# STM32H7RSxx register map
File version: 0.2
CPU: CM7 r0p1, little endian, MPU, FPU, 4 interrupt priority bits
Registers are 32-bit, read-write, reset 0x0 unless marked. A register's access mark holds for its fields unless they carry their own. Offsets are from the block's base; [hi:lo] are bit positions; <NAME> marks a mode.

## ADF — Audio digital filter
Base 0x4002F000
0x00 ADF_GCR — ADF global control register
  [0] TRGO — Trigger output control This bit is set by software and reset by hardware. It is used to start the acquisition of several filters synchronously. It is also used to synchronize several ADF together by controlling the adf_trgo signal.
    0=Write 0 has no effect. Read 0 means that the trigger can be set again to 1.; 1=Write 1 generates a positive pulse on the adf_trgo signal and triggers the acquisition on enabled filter having their ACQMOD[2:0] = 01x and selecting TRGO as trigger. Read 1 means that the trigger pulse is still active.
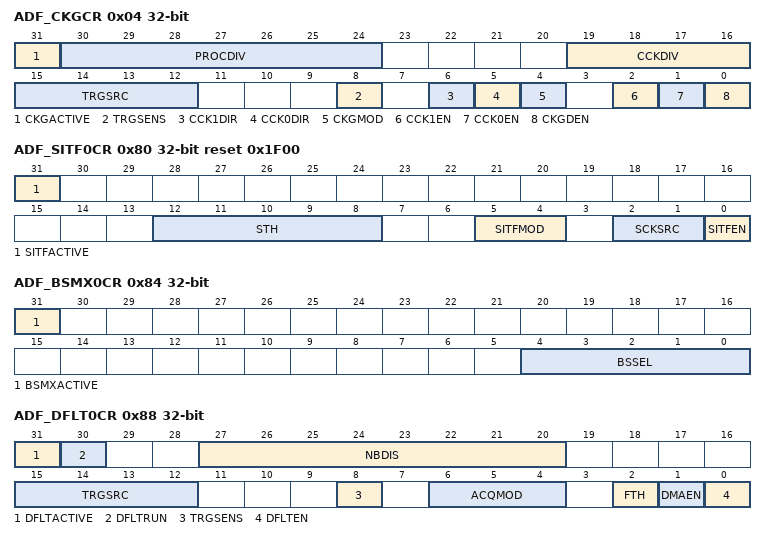
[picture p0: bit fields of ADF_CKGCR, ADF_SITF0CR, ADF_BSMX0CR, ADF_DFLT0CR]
0x04 ADF_CKGCR access per field — ADF clock generator control register
  [31] CKGACTIVE ro — Clock generator active flag This bit is set and cleared by hardware. Ii is used by the application to check if the clock generator is effectively enabled (active) or not. The protected fields of this function can only be updated when CKGACTIVE = 0 (see Section 46.4.13: Register protection for details). The delay between a transition on CKGDEN and a transition on CKGACTIVE is two periods of AHB clock and two 2 periods of adf_proc_ck.
    0=The clock generator is not active and can be configured if needed; 1=The clock generator is active and protected fields cannot be configured
  [30:24] PROCDIV rw — Divider to control the serial interface clock this field is set and reset by software. It is used to adjust the frequency of the clock provided to the SITF. This field must not be changed if the filter is enabled (DFTEN = 1). ... Note: This field can be write-protected (see Section 46.4.13: Register protection for details).
    0=adf_ker_ck provided to the SITF; 1=adf_ker_ck / 2 provided to the SITF
  [19:16] CCKDIV rw — Divider to control the ADF_CCK clock This field is set and reset by software. It is used to adjust the frequency of the ADF_CCK clock. The input clock of this divider is the clock provided to the SITF. More globally, the frequency of the ADF_CCK is given by the following formula: This field must not be changed if the filter is enabled (DFTEN = 1). ... Note: This field can be write-protected (see Section 46.4.13: Register protection for details).
    0=The ADF_CCK clock is adf_proc_ck; 1=The ADF_CCK clock is adf_proc_ck / 2; 2=The ADF_CCK clock is adf_proc_ck / 3; 15=The ADF_CCK clock is adf_proc_ck / 16
  [15:12] TRGSRC rw — Digital filter trigger signal selection This field is set and cleared by software. It is used to select which external signals trigger the corresponding filter. This field is not significant if the CKGMOD = 0. 000x: TRGO selected others: reserved Note: This field can be write-protected (see Section 46.4.13: Register protection for details).
    2=adf_trg1 selected
  [8] TRGSENS rw — CKGEN trigger sensitivity selection This bit is set and cleared by software. It is used to select the trigger sensitivity of the trigger signals. This bit is not significant if the CKGMOD = 0. Note: When the trigger source is TRGO, the sensitivity is forced to falling edge, thus TRGSENS value is not taken into account. This bit can be write-protected (see Section 46.4.13: Register protection for details).
    0=A rising edge event triggers the activation of CKGEN dividers; 1=A falling edge even triggers the activation of CKGEN dividers
  [6] CCK1DIR rw — ADF_CCK1 direction This bit is set and reset by software. It is used to control the direction of the ADF_CCK1 pin. Note: This bit can be write-protected (see Section 46.4.13: Register protection for details).
    0=The ADF_CCK1 pin direction is in input; 1=The ADF_CCK1 pin direction is in output
  [5] CCK0DIR rw — ADF_CCK0 direction This bit is set and reset by software. It is used to control the direction of the ADF_CCK0 pin. Note: This bit can be write-protected (see Section 46.4.13: Register protection for details).
    0=The ADF_CCK0 pin direction is in input; 1=The ADF_CCK0 pin direction is in output
  [4] CKGMOD rw — Clock generator mode This bit is set and reset by software. It is used to define the way the clock generator is enabled. This bit must not be changed if the filter is enabled (DFTEN = 1). Note: This bit can be write-protected (see Section 46.4.13: Register protection for details).
    0=The kernel clock is provided to the dividers as soon as CKGDEN is set to 1; 1=The kernel clock is provided to the dividers when CKGDEN is set to 1 and the trigger condition met
  [2] CCK1EN rw — ADF_CCK1 clock enable This bit is set and reset by software. It is used to control the generation of the bitstream clock on the ADF_CCK1 pin.
    0=Bitstream clock not generated; 1=Bitstream clock generated on the ADF_CCK1 pin
  [1] CCK0EN rw — ADF_CCK0 clock enable This bit is set and reset by software. It is used to control the generation of the bitstream clock on the ADF_CCK0 pin.
    0=Bitstream clock not generated; 1=Bitstream clock generated on the ADF_CCK0 pin
  [0] CKGDEN rw — CKGEN dividers enable This bit is set and reset by software. It is used to enable/disable the clock dividers of the CKGEN: PROCDIV and CCKDIV.
    0=CKGEN dividers disabled; 1=CKGEN dividers enabled
0x80 ADF_SITF0CR access per field reset 0x1F00 — ADF serial interface control register 0
  [31] SITFACTIVE ro — Serial interface active flag This bit is set and cleared by hardware. It is used by the application to check if the serial interface is effectively enabled (active) or not. The protected fields of this function can only be updated when SITFACTIVE is set to 0 (see Section 46.4.13: Register protection for details). The delay between a transition on SITFEN and a transition on SITFACTIVE is two periods of AHB clock and two periods of adf_proc_ck.
    0=The serial interface is not active, and can be configured if needed; 1=The serial interface is active and protected fields cannot be configured
  [12:8] STH rw — Manchester symbol threshold/SPI threshold This field is set and cleared by software. It is used for Manchester mode to define the expected symbol threshold levels (seer to Manchester mode for details on computation). In addition this field is used to define the timeout value for the clock absence detection in Normal SPI mode. STH[4:0] values lower than four are invalid. Note: This field can be write-protected (see Section 46.4.13: Register protection for details).
  [5:4] SITFMOD rw — Serial interface type This field is set and cleared by software. It is used to define the serial interface type. Note: This field can be write-protected (see Section 46.4.13: Register protection for details).
    0=LF_MASTER SPI mode; 1=Normal SPI mode; 2=Manchester mode: rising edge = logic 0, falling edge = logic 1; 3=Manchester mode: rising edge = logic 1, falling edge = logic 0
  [2:1] SCKSRC rw — Serial clock source This field is set and cleared by software. It is used to select the clock source of the serial interface. others: reserved Note: This field can be write-protected (see Section 46.4.13: Register protection for details).
    0=Serial clock source is ADF_CCK0; 1=Serial clock source is ADF_CCK1
  [0] SITFEN rw — Serial interface enable This bit is set and cleared by software. It is used to enable/disable the serial interface.
    0=Serial interface disabled; 1=Serial interface enabled
0x84 ADF_BSMX0CR access per field — ADF bitstream matrix control register 0
  [31] BSMXACTIVE ro — BSMX active flag This bit is set and cleared by hardware. It is used by the application to check if the BSMX is effectively enabled (active) or not. BSSEL[4:0] can only be updated when BSMXACTIVE is set to 0. This BSMXACTIVE flag cannot go to 0 if DFLT0 is enabled.
    0=BSMX is not active and can be configured if needed; 1=BSMX is active and protected fields cannot be configured
  [4:0] BSSEL rw — Bitstream selection This field is set and cleared by software. It is used to select the bitstream to be processed for DFLT0. others: reserved Note: This field can be write-protected (see Section 46.4.13: Register protection for details).
    0=bs0_r provided to DFLT0; 1=bs0_f provided to DFLT0
0x88 ADF_DFLT0CR access per field — ADF digital filter control register 0
  [31] DFLTACTIVE ro — DFLT0 active flag This bit is set and cleared by hardware. It indicates if DFLT0 is active: can be running or waiting for events.
    0=DFLT0 not active (can be re-enabled again, via DFLTEN bit, if needed); 1=DFLT0 active
  [30] DFLTRUN ro — DFLT0 run status flag This bit is set and cleared by hardware. It indicates if DFLT0 is running or not.
    0=DFLT0 not running and ready to accept a new trigger event; 1=DFLT0running
  [27:20] NBDIS rw — Number of samples to be discarded This field is set and cleared by software. It is used to define the number of samples to be discarded every time DFLT0 is re-started. ... Note: This field can be write-protected (see Section 46.4.13: Register protection for details).
    0=No sample discarded; 1=1 sample discarded
  [15:12] TRGSRC rw — DFLT0 trigger signal selection This field is set and cleared by software. It is used to select which external signals trigger DFLT0. others: Reserved Note: This field can be write-protected (see Section 46.4.13: Register protection for details).
    0=TRGO selected; 2=adf_trgi selected
  [8] TRGSENS rw — DFLT0 trigger sensitivity selection This field is set and cleared by software. It is used to select the trigger sensitivity of the external signals When the trigger source is TRGO, TRGSENS value is not taken into account. When TRGO is selected, the sensitivity is forced to falling edge. Note: This bit can be write-protected (see Section 46.4.13: Register protection for details).
    0=A rising edge event triggers the acquisition; 1=A falling edge even triggers the acquisition
  [6:4] ACQMOD rw — DFLT0 trigger mode This field is set and cleared by software. It is used to select the filter trigger mode. others: same as 000 Note: This field can be write-protected (see Section 46.4.13: Register protection for details)..
    0=Asynchronous continuous acquisition mode; 1=Asynchronous single-shot acquisition mode; 2=Synchronous continuous acquisition mode; 3=Synchronous single-shot acquisition mode; 4=Window continuous acquisition mode
  [2] FTH rw — RXFIFO threshold selection This bit is set and cleared by software. It is used to select the RXFIFO threshold. Note: This bit can be write-protected (see Section 46.4.13: Register protection for details).
    0=RXFIFO threshold event generated when the RXFIFO is not empty; 1=RXFIFO threshold event generated when the RXFIFO is half-full
  [1] DMAEN rw — DMA requests enable This bit is set and cleared by software. It is used to control the generation of DMA request to transfer the processed samples into the memory. Note: This bit can be write-protected (see Section 46.4.13: Register protection for details).
    0=DMA interface for the corresponding digital filter disabled; 1=DMA interface for the corresponding digital filter enabled
  [0] DFLTEN wo — DFLT0 enable This bit is set and cleared by software. It is used to control the start of acquisition of the DFLT0 path. This bit behavior depends on ACQMOD[2:0] and external events. The serial or parallel interface delivering the samples must be enabled as well.
    0=Acquisition immediately stopped; 1=Acquisition immediately started if ACQMOD[2:0] = 00x or 101, or acquisition started when the proper trigger event occurs if ACQMOD[2:0] = 01x
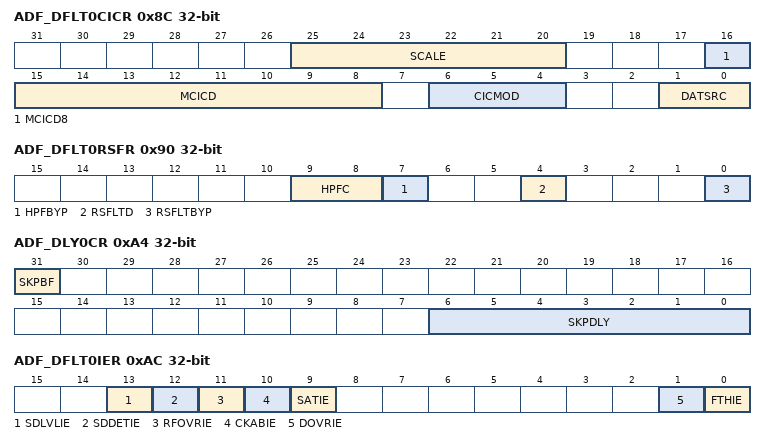
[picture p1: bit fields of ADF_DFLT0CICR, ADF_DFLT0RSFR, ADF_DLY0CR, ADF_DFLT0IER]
0x8C ADF_DFLT0CICR — ADF digital filer configuration register 0
  [25:20] SCALE — Scaling factor selection This field is set and cleared by software. It is used to select the gain to be applied at CIC output (see Table 419 for details). If the application attempts to write a new gain value while the previous one is not yet applied, this new gain value is ignored. Reading back this field informs the application on the current gain value. ... ... others: Reserved
    0=0 dB; 1=+ 3.5 dB; 2=+ 6 dB or shift left by 1 bit; 24=+ 72 dB or shift left by 12 bits; 32=- 48.2 dB or shift right by 8 bits (default value); 33=- 44.6 dB; 34=- 42.1 dB or shift right by 7 bits; 35=- 38.6 dB; 46=-6 dB or shift right by 1 bit; 47=-2.5 dB
  [16] MCICD8 — CIC decimation ratio selection This field is set and cleared by software.It is used to select the CIC decimation ratio. A decimation ratio smaller than two is not allowed. The decimation ratio is given by (CICDEC+1). ... Note: This field can be write-protected (see Section 46.4.13: Register protection for details).
    0=Decimation ratio is 2; 1=Decimation ratio is 2
  [15:8] MCICD — CIC decimation ratio selection This field is set and cleared by software.It is used to select the CIC decimation ratio. A decimation ratio smaller than two is not allowed. The decimation ratio is given by (CICDEC+1). ... Note: This field can be write-protected (see Section 46.4.13: Register protection for details).
    0=Decimation ratio is 2; 1=Decimation ratio is 2
  [6:4] CICMOD — Select the CIC order This field is set and cleared by software. It is used to select the order of the MCIC. others: reserved Note: This field can be write-protected (see Section 46.4.13: Register protection for details).
    4=MCIC configured in single Sinc<sup>4</sup> filter; 5=MCIC configured in single Sinc<sup>5</sup> filter
  [1:0] DATSRC — Source data for the digital filter This field is set and cleared by software. 0x: Stream coming from the BSMX selected Note: This field can be write-protected (see Section 46.4.13: Register protection for details).
    2=Stream coming from the ADCITF1 selected; 3=Stream coming from the ADCITF2 selected
0x90 ADF_DFLT0RSFR — ADF reshape filter configuration register 0
  [9:8] HPFC — High-pass filter cut-off frequency This field is set and cleared by software. it is used to select the cut-off frequency of the high-pass filter. F<sub>PCM</sub> represents the sampling frequency at HPF input. Note: This field can be write-protected (see Section 46.4.13: Register protection for details).
    0=Cut-off frequency = 0.000625 x FPCM; 1=Cut-off frequency = 0.00125 x FPCM; 2=Cut-off frequency = 0.00250 x FPCM; 3=Cut-off frequency = 0.00950 x FPCM
  [7] HPFBYP — High-pass filter bypass This bit is set and cleared by software. It is used to bypass the high-pass filter. Note: This bit can be write-protected (see Section 46.4.13: Register protection for details).
    0=HPF not bypassed (default value); 1=HPF bypassed
  [4] RSFLTD — Reshaper filter decimation ratio This bit is set and cleared by software. It is used to select the decimation ratio for the reshape filter Note: This bit can be write-protected (see Section 46.4.13: Register protection for details).
    0=Decimation ratio is 4 (default value); 1=Decimation ratio is 1
  [0] RSFLTBYP — Reshaper filter bypass This bit is set and cleared by software. It is used to bypass the reshape filter and its decimation block. Note: This bit can be write-protected (see Section 46.4.13: Register protection for details).
    0=Reshape filter not bypassed (default value); 1=Reshape filter bypassed
0xA4 ADF_DLY0CR access per field — ADF delay control register 0
  [31] SKPBF ro — Skip busy flag This bit is set and cleared by hardware. It is used to control if the delay sequence is completed.
    0=ADF ready to accept a new value into SKPDLY[6:0]; 1=Last valid SKPDLY[6:0] still under precessing
  [6:0] SKPDLY rw — Delay to apply to a bitstream This field is set and cleared by software. It defines the number of input samples that are skipped. Skipping is applied immediately after writing to this field, if SKPBF = 0 and DFLTEN = 1. If SKPBF = 1, the value written into the register is ignored by the delay state machine. ...
    0=No input sample skipped; 1=1 input sample skipped
0xAC ADF_DFLT0IER — ADF DFLT0 interrupt enable register
  [13] SDLVLIE — SAD sound-level value ready enable This bit is set and cleared by software.
    0=Sound-level-ready interrupt disabled; 1=Sound-level-ready interrupt enabled
  [12] SDDETIE — Sound activity detection interrupt enable This bit is set and cleared by software.
    0=Sound-trigger interrupt disabled; 1=Sound-trigger interrupt enabled
  [11] RFOVRIE — Reshape filter overrun interrupt enable This bit is set and cleared by software.
    0=Reshape filter overrun interrupt disabled; 1=Reshape filter overrun interrupt enabled
  [10] CKABIE — Clock absence detection interrupt enable This bit is set and cleared by software.
    0=Clock absence interrupt disabled; 1=Clock absence interrupt enabled
  [9] SATIE — Saturation detection interrupt enable This bit is set and cleared by software.
    0=Saturation interrupt disabled; 1=Saturation interrupt enabled
  [1] DOVRIE — Data overflow interrupt enable This bit is set and cleared by software.
    0=Data overflow interrupt disabled; 1=Data overflow interrupt enabled
  [0] FTHIE — RXFIFO threshold interrupt enable This bit is set and cleared by software.
    0=RXFIFO threshold interrupt disabled; 1=RXFIFO threshold interrupt enabled
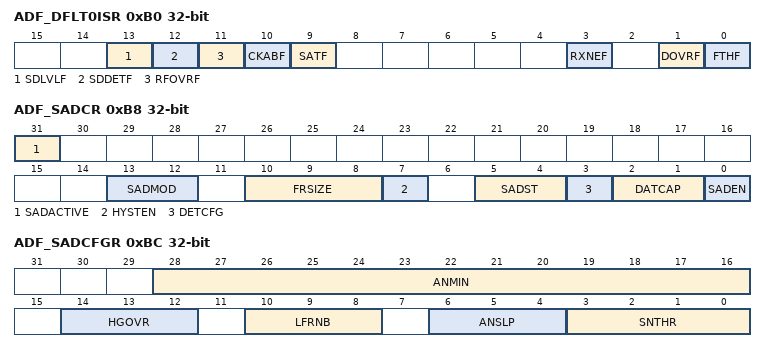
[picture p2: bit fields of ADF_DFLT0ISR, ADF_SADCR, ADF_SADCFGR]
0xB0 ADF_DFLT0ISR access per field — ADF DFLT0 interrupt status register 0
  [13] SDLVLF rw — Sound level value ready flag This bit is set by hardware and cleared by software by writing this bit to 1.
    0=Read 0 means that new sound level value is not ready. Write 0 has no effect.; 1=Read 1 means that new sound level value is ready. Write 1 clears this flag.
  [12] SDDETF rw — Sound activity detection flag This bit is set by hardware and cleared by software by writing this bit to 1.
    0=Read 0 means that no sound activity is detected. Write 0 has no effect.; 1=Read 1 means that sound activity is detected. Write 1 clears this flag.
  [11] RFOVRF rw — Reshape filter overrun detection flag This bit is set by hardware and cleared by software by writing this bit to 1.
    0=Read 0 means that no reshape filter overrun is detected. Write 0 has no effect.; 1=Read 1 means that reshape filter overrun is detected. Write 1 clears this flag.
  [10] CKABF rw — Clock absence detection flag This bit is set by hardware and cleared by software by writing this bit to 1.
    0=Read 0 means that no clock absence is detected. Write 0 has no effect.; 1=Read 1 means that a clock absence is detected. Write 1 clears this flag.
  [9] SATF rw — Saturation detection flag This bit is set by hardware and cleared by software by writing this bit to 1.
    0=Read 0 means that no saturation is detected. Write 0 has no effect.; 1=Read 1 means that a saturation is detected. Write 1 clears this flag.
  [3] RXNEF ro — RXFIFO not empty flag This bit is set and cleared by hardware according to the RXFIFO level.
    0=RXFIFO empty; 1=RXFIFO not empty
  [1] DOVRF rw — Data overflow flag This bit is set by hardware and cleared by software by writing this bit to 1.
    0=Read 0 means that no overflow is detected. Write 0 has no effect.; 1=Read 1 means that an overflow is detected; Write 1 clears this flag
  [0] FTHF ro — RXFIFO threshold flag This bit is set by hardware, and cleared by the hardware when the RXFIFO level is lower than the threshold.
    0=RXFIFO threshold not reached; 1=RXFIFO threshold reached
0xB8 ADF_SADCR access per field — ADF SAD control register
  [31] SADACTIVE ro — SAD Active flag This bit is set and cleared by hardware. It is used to check if the SAD is effectively enabled (active) or not. The protected fields and registers of this function can only be updated when the SADACTIVE is set to 0 (see Section 46.4.13: Register protection for details). The delay between a transition on SADEN and a transition on SADACTIVE is two periods of AHB clock and two periods of adf_proc_ck.
    0=SAD not active and can be configured if needed; 1=SAD active and protected fields cannot be configured
  [13:12] SADMOD rw — SAD working mode This field is set and cleared by software. It is used to define the way the SAD works. The SAD triggers when the sound level (SDLVL) is bigger than the defined threshold. In this mode, the SAD works like a voice activity detector. The SAD triggers when the sound level (SDLVL) is bigger than the defined threshold. In this mode, the SAD works like a sound detector. 1x: Threshold value given by 4 x ANMIN[12:0] The SAD triggers when the estimated ambient noise (ANLVL), multiplied by the gain selected by SNTHR[3:0] is bigger than the defined threshold. In this mode, the SAD is working like an ambient noise estimator. Hysteresis function cannot be used in this mode. Note: This field can be write-protected (see Section 46.4.13: Register protection for details).
    0=Threshold value computed according to the estimated ambient noise; 1=Threshold value equal to ANMIN[12:0], multiplied by the gain selected by SNTHR[3:0]
  [10:8] FRSIZE rw — Frame size This field is set and cleared by software. it is used to define the size of one frame and also to define how many samples are taken into account to compute the short-term signal level. 11x: 512 PCM samples used to compute the short-term signal level Note: This field can be write-protected (see Section 46.4.13: Register protection for details).
    0=8 PCM samples used to compute the short-term signal level; 1=16 PCM samples used to compute the short-term signal level; 2=32 PCM samples used to compute the short-term signal level; 3=64 PCM samples used to compute the short-term signal level; 4=128 PCM samples used to compute the short-term signal level; 5=256 PCM samples used to compute the short-term signal level
  [7] HYSTEN rw — Hysteresis enable This bit is set and cleared by software. It is used to enable/disable the hysteresis function (see Table 419 for details). This bit must be kept to 0 when SADMOD[1:0] = 1x. Note: This bit can be write-protected (see Section 46.4.13: Register protection for details).
    0=Hysteresis function disabled. THR<sub>H</sub> is always used.; 1=Hysteresis function enabled. THR<sub>H</sub> is used for MONITOR to DETECT transition and THR<sub>L</sub> is used for DETECT to MONITOR transition.
  [5:4] SADST ro — SAD state This field is set and cleared by hardware. It indicates the SAD state and is meaningful only when SADEN = 1. The SAD state can be: - LEARN when the SAD is in learning phase or in SDLVL computation mode - MONITOR when the SAD is in monitoring phase - DETECT when the SAD detects a sound
    0=SAD in LEARN state; 1=SAD in MONITOR state; 3=SAD in DETECT state
  [3] DETCFG rw — Sound trigger event configuration This bit is set and cleared by software. It is used to define if the sddet_evt event is generated only when the SAD enters to MONITOR state or when the SAD enters or exits the DETECT state. Note: This bit can be write-protected (see Section 46.4.13: Register protection for details).
    0=sddet_evt generated when SAD enters the MONITOR state; 1=sddet_evt generated when SAD enters or exits the DETECT state
  [2:1] DATCAP rw — Data capture mode This field is set and cleared by software. It is used to define in which conditions, the samples provided by DLFT0 are stored into the memory. 1x: Samples from DFLT0 transfered into memory when SAD and DFLT0 are enabled Note: This field can be write-protected (see Section 46.4.13: Register protection for details).
    0=Samples from DFLT0 not transfered into the memory; 1=Samples from DFLT0 transfered into the memory when SAD is in DETECT state
  [0] SADEN rw — Sound activity detector enable This bit is set and cleared by software. It is used to enable/disable the SAD.
    0=SAD disabled and SAD state reset; 1=SAD enabled
0xBC ADF_SADCFGR — ADF SAD configuration register
  [28:16] ANMIN — Minimum noise level This field is set and cleared by software. It is used to define the minimum noise level and then the sensitivity. It represents a positive number. Note: This field can be write-protected (see Section 46.4.13: Register protection for details).
  [14:12] HGOVR — Hangover time window This field is set and cleared by software. Once the SAD state is DETECT, this parameter is used to define the amount of time the sound is allowed to remain below the threshold, before switching the SAD to MONITOR state (see FRSIZE field for the description of a frame). Note: This field can be write-protected (see Section 46.4.13: Register protection for details).
    0=SAD back to MONITOR state if sound is below threshold for 4 frames; 1=SAD back to MONITOR state if sound is below threshold for 8 frames; 2=SAD back to MONITOR state if sound is below threshold for 16 frames; 3=SAD back to MONITOR state if sound is below threshold for 32 frames; 4=SAD back to MONITOR state if sound is below threshold for 64 frames; 5=SAD back to MONITOR state if sound is below threshold for 128 frames; 6=SAD back to MONITOR state if sound is below threshold for 256 frames; 7=SAD back to MONITOR state if sound is below threshold for 512 frames
  [10:8] LFRNB — Number of learning frames This field is set and cleared by software. It is used to define the number of learning frames to perform the first estimate of the noise level. 1xx: 32 frames used to compute the initial noise level Note: This field can be write-protected (see Section 46.4.13: Register protection for details).
    0=2 frames used to compute the initial noise level; 1=4 frames used to compute the initial noise level; 2=8 frames used to compute the initial noise level; 3=16 frames used to compute the initial noise level
  [6:4] ANSLP — Ambient noise slope control This field is set and cleared by software. It is used to define the positive and negative slope of the noise estimator, in charge of updating the ANLVL (see Ambient noise estimation (ANLVL) for information about programming this field). Note: This field can be write-protected (see Section 46.4.13: Register protection for details).
  [3:0] SNTHR — Signal to noise threshold This field is set and cleared by software. It is used to define THR<sub>H </sub>(and THR<sub>L</sub> if hysteresis is enabled). See Table 419 for details. others: Reserved Note: This field can be write-protected (see Section 46.4.13: Register protection for details).
    0=THR<sub>H </sub>is 3.5 dB higher than ANLVL; 1=THR<sub>H </sub>is 6.0 dB higher than ANLVL; 2=THR<sub>H </sub>is 9.5 dB higher than ANLVL; 3=THR<sub>H </sub>is 12 dB higher than ANLVL; 4=THR<sub>H </sub>is 15.6 dB higher than ANLVL; 5=THR<sub>H </sub>is 18 dB higher than ANLVL; 6=THR<sub>H </sub>is 21.6 dB higher than ANLVL; 7=THR<sub>H </sub>is 24.1 dB higher than ANLVL; 8=THR<sub>H </sub>is 27.6 dB higher than ANLVL; 9=THR<sub>H </sub>is 30.1dB higher than ANLVL
0xC0 ADF_SADSDLVR ro — ADF SAD sound level register
  [14:0] SDLVL — Short term sound level This field is set by hardware. It contains the latest sound level computed by the SAD. To refresh this value, SDLVLF must be cleared.
0xC4 ADF_SADANLVR ro — ADF SAD ambient noise level register
  [14:0] ANLVL — Ambient noise level estimation This field is set by hardware. It contains the latest ambient noise level computed by the SAD. To refresh this field, the SDLVLF flag must be cleared.
0xF0 ADF_DFLT0DR ro — ADF digital filter data register 0
  [31:8] DR — Data processed by DFT0
